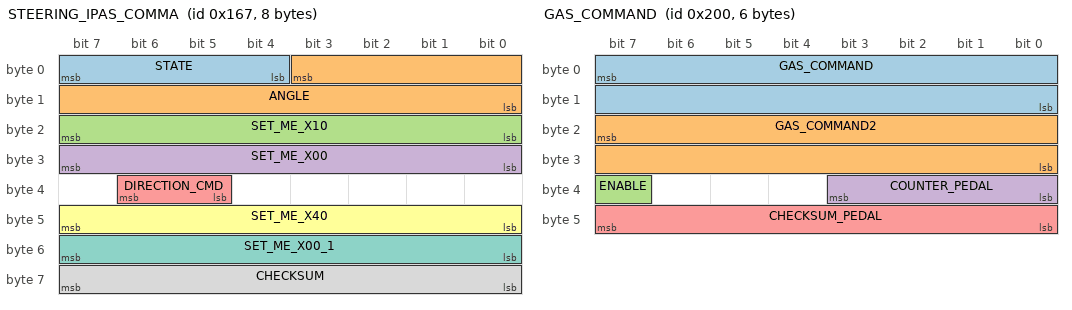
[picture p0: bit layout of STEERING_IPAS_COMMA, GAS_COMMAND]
BO_ 359 STEERING_IPAS_COMMA: 8 IPAS
 SG_ STATE : 7|4@0+ (1,0) [0|15] "" XXX
 SG_ ANGLE : 3|12@0- (1.5,0) [-510|510] "deg" XXX
 SG_ SET_ME_X10 : 23|8@0+ (1,0) [0|255] "" XXX
 SG_ SET_ME_X00 : 31|8@0+ (1,0) [0|255] "" XXX
 SG_ DIRECTION_CMD : 38|2@0+ (1,0) [0|3] "" XXX
 SG_ SET_ME_X40 : 47|8@0+ (1,0) [0|255] "" XXX
 SG_ SET_ME_X00_1 : 55|8@0+ (1,0) [0|255] "" XXX
 SG_ CHECKSUM : 63|8@0+ (1,0) [0|255] "" XXX

CM_ "BO_ STEERING_IPAS_COMMA: Copy of msg 614 so we can do angle control while the Park Assist ECU is connected (Panda spoofs 614 with 359 on connector J70). Note that addresses 0x266 and 0x167 are checksum-invariant";

BO_ 512 GAS_COMMAND: 6 EON
 SG_ GAS_COMMAND : 7|16@0+ (0.159375,-75.555) [0|1] "" INTERCEPTOR
 SG_ GAS_COMMAND2 : 23|16@0+ (0.159375,-151.111) [0|1] "" INTERCEPTOR
 SG_ ENABLE : 39|1@0+ (1,0) [0|1] "" INTERCEPTOR
 SG_ COUNTER_PEDAL : 35|4@0+ (1,0) [0|15] "" INTERCEPTOR
 SG_ CHECKSUM_PEDAL : 47|8@0+ (1,0) [0|255] "" INTERCEPTOR

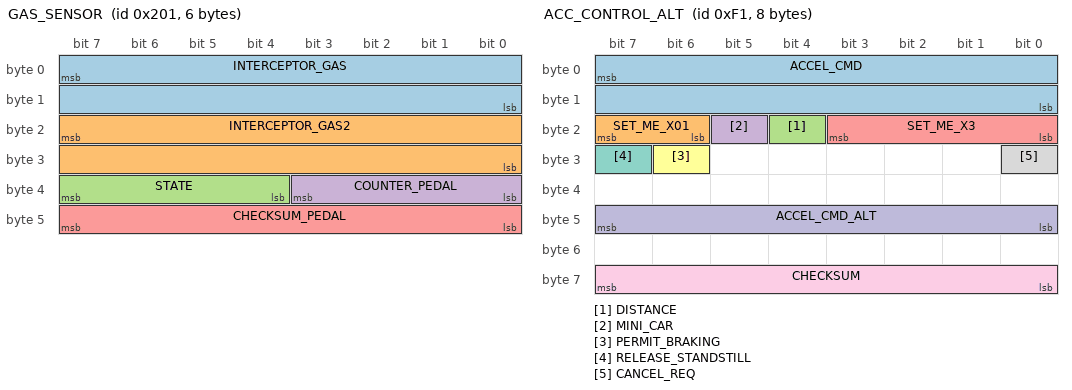
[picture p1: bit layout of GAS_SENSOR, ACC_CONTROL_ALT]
BO_ 513 GAS_SENSOR: 6 INTERCEPTOR
 SG_ INTERCEPTOR_GAS : 7|16@0+ (0.159375,-75.555) [0|1] "" EON
 SG_ INTERCEPTOR_GAS2 : 23|16@0+ (0.159375,-151.111) [0|1] "" EON
 SG_ STATE : 39|4@0+ (1,0) [0|15] "" EON
 SG_ COUNTER_PEDAL : 35|4@0+ (1,0) [0|15] "" EON
 SG_ CHECKSUM_PEDAL : 47|8@0+ (1,0) [0|255] "" EON

VAL_ 513 STATE 5 "FAULT_TIMEOUT" 4 "FAULT_STARTUP" 3 "FAULT_SCE" 2 "FAULT_SEND" 1 "FAULT_BAD_CHECKSUM" 0 "NO_FAULT" ;

BO_ 35 SECONDARY_STEER_ANGLE: 8 XXX
 SG_ ZORRO_STEER : 7|24@0- (0.004901594652,0) [-500|500] "" XXX

CM_ "BO_ SECONDARY_STEER_ANGLE: ZSS is a high-precision steering angle sensor that can replace the lower resolution sensor in most TSS1 Toyotas. Learn more: https://github.com/commaai/openpilot/wiki/Toyota-Lexus#zorro-steering-sensor-zss";

BO_ 241 ACC_CONTROL_ALT: 8 EON
 SG_ ACCEL_CMD : 7|16@0- (0.001,0) [-20|20] "m/s2" HCU
 SG_ SET_ME_X01 : 23|2@0+ (1,0) [0|3] "" HCU
 SG_ DISTANCE : 20|1@0+ (1,0) [0|1] "" XXX
 SG_ MINI_CAR : 21|1@0+ (1,0) [0|1] "" XXX
 SG_ SET_ME_X3 : 19|4@0+ (1,0) [0|15] "" XXX
 SG_ PERMIT_BRAKING : 30|1@0+ (1,0) [0|1] "" HCU
 SG_ RELEASE_STANDSTILL : 31|1@0+ (1,0) [0|1] "" HCU
 SG_ CANCEL_REQ : 24|1@0+ (1,0) [0|1] "" HCU
 SG_ CHECKSUM : 63|8@0+ (1,0) [0|255] "" XXX
 SG_ ACCEL_CMD_ALT : 47|8@0- (0.05,0) [0|0] "m/s^2" XXX

BO_ 242 PRECOLLISION_2_ALT: 8 EON
 SG_ DECELERATION : 7|10@0- (0.1,0) [0|0] "m/s^2" Vector__XXX
 SG_ DS1STAT2 : 13|3@0+ (1,0) [0|0] "" Vector__XXX
 SG_ DS1STBK2 : 10|3@0+ (1,0) [0|0] "" Vector__XXX
 SG_ PCSWAR : 18|1@0+ (1,0) [0|0] "" FCM
 SG_ PCSALM : 17|1@0+ (1,0) [0|0] "" FCM
 SG_ PCSOPR : 16|1@0+ (1,0) [0|0] "" Vector__XXX
 SG_ PCSABK : 31|1@0+ (1,0) [0|0] "" Vector__XXX
 SG_ PBATRGR : 30|2@0+ (1,0) [0|0] "" Vector__XXX
 SG_ PPTRGR : 28|1@0+ (1,0) [0|0] "" FCM
 SG_ IBTRGR : 27|1@0+ (1,0) [0|0] "" FCM
 SG_ CLEXTRGR : 26|1@0+ (1,0) [0|0] "" Vector__XXX
 SG_ IRLT_REQ : 25|2@0+ (1,0) [0|0] "" Vector__XXX
 SG_ BRKHLD : 37|1@0+ (1,0) [0|0] "" Vector__XXX
 SG_ AVSTRGR : 36|1@0+ (1,0) [0|0] "" SCS
 SG_ VGRSTRGR : 35|2@0+ (1,0) [0|0] "" Vector__XXX
 SG_ PREFILL : 33|1@0+ (1,0) [0|0] "" Vector__XXX
 SG_ PBRTRGR : 32|1@0+ (1,0) [0|0] "" Vector__XXX
 SG_ PCSDIS : 43|1@0+ (1,0) [0|0] "" Vector__XXX
 SG_ PBPREPMP : 40|1@0+ (1,0) [0|0] "" Vector__XXX
 SG_ CHECKSUM : 63|8@0+ (1,0) [0|0] "" FCM
BO_ 767 SDSU: 8 XXX
 SG_ FD_BUTTON : 7|1@0+ (1,0) [0|1] "" XXX

CM_ "BO_ SDSU: The sDSU is a modified DSU for use in TSS1 Toyotas. Learn more: https://github.com/wocsor/panda/tree/smart_dsu";
CM_ SG_ 767 FD_BUTTON "The follow distance button signal as forwarded by the sdsu";
